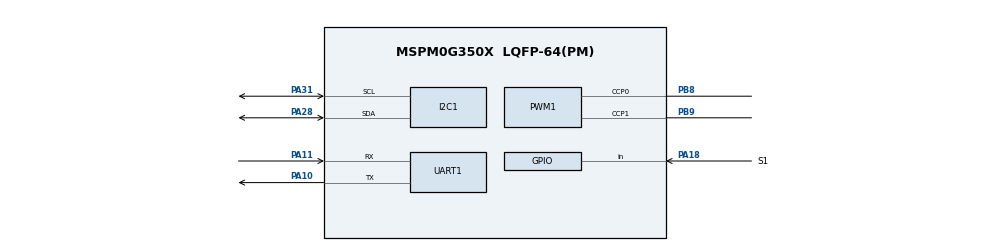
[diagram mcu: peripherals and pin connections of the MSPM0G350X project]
/**
 * @cliArgs --device "MSPM0G350X" --package "LQFP-64(PM)" --part "Default" --product "mspm0_sdk@2.01.00.03"
 * @versions {"tool":"1.20.0+3587"}
 */

/**
 * Import the modules used in this configuration.
 */
const GPIO   = scripting.addModule("/ti/driverlib/GPIO", {}, false);
const GPIO1  = GPIO.addInstance();
const GPIO2  = GPIO.addInstance();
const GPIO3  = GPIO.addInstance();
const GPIO4  = GPIO.addInstance();
const I2C    = scripting.addModule("/ti/driverlib/I2C", {}, false);
const I2C1   = I2C.addInstance();
const PWM    = scripting.addModule("/ti/driverlib/PWM", {}, false);
const PWM1   = PWM.addInstance();
const SYSCTL = scripting.addModule("/ti/driverlib/SYSCTL");
const TIMER  = scripting.addModule("/ti/driverlib/TIMER", {}, false);
const TIMER1 = TIMER.addInstance();
const UART   = scripting.addModule("/ti/driverlib/UART", {}, false);
const UART1  = UART.addInstance();
const UART2  = UART.addInstance();

/**
 * Write custom configuration values to the imported modules.
 */
const gate7  = system.clockTree["MFCLKGATE"];
gate7.enable = true;

GPIO1.$name                          = "GPIO_LEDS";
GPIO1.associatedPins.create(3);
GPIO1.associatedPins[0].$name        = "LED_1";
GPIO1.associatedPins[0].assignedPort = "PORTB";
GPIO1.associatedPins[0].assignedPin  = "22";
GPIO1.associatedPins[1].$name        = "LED_2";
GPIO1.associatedPins[1].assignedPort = "PORTB";
GPIO1.associatedPins[1].assignedPin  = "26";
GPIO1.associatedPins[2].$name        = "LED_3";
GPIO1.associatedPins[2].assignedPort = "PORTB";
GPIO1.associatedPins[2].assignedPin  = "27";

const Board = scripting.addModule("/ti/driverlib/Board", {}, false);

GPIO2.$name                              = "GPIO_KEYS";
GPIO2.associatedPins.create(2);
GPIO2.associatedPins[0].$name            = "S1";
GPIO2.associatedPins[0].direction        = "INPUT";
GPIO2.associatedPins[0].assignedPort     = "PORTA";
GPIO2.associatedPins[0].assignedPin      = "18";
GPIO2.associatedPins[0].internalResistor = "PULL_DOWN";
GPIO2.associatedPins[0].interruptEn      = true;
GPIO2.associatedPins[0].polarity         = "RISE_FALL";
GPIO2.associatedPins[0].pin.$assign      = "PA18";
GPIO2.associatedPins[1].$name            = "S2";
GPIO2.associatedPins[1].internalResistor = "PULL_UP";
GPIO2.associatedPins[1].assignedPort     = "PORTB";
GPIO2.associatedPins[1].assignedPin      = "21";
GPIO2.associatedPins[1].direction        = "INPUT";
GPIO2.associatedPins[1].interruptEn      = true;
GPIO2.associatedPins[1].polarity         = "RISE";

GPIO3.$name                          = "GPIO_Encoders";
GPIO3.associatedPins.create(4);
GPIO3.associatedPins[0].direction    = "INPUT";
GPIO3.associatedPins[0].assignedPort = "PORTB";
GPIO3.associatedPins[0].assignedPin  = "0";
GPIO3.associatedPins[0].interruptEn  = true;
GPIO3.associatedPins[0].polarity     = "RISE_FALL";
GPIO3.associatedPins[0].$name        = "M2_B0_TI1";
GPIO3.associatedPins[1].direction    = "INPUT";
GPIO3.associatedPins[1].assignedPort = "PORTB";
GPIO3.associatedPins[1].assignedPin  = "1";
GPIO3.associatedPins[1].polarity     = "RISE_FALL";
GPIO3.associatedPins[1].$name        = "M2_B1_TI2";
GPIO3.associatedPins[2].direction    = "INPUT";
GPIO3.associatedPins[2].polarity     = "RISE_FALL";
GPIO3.associatedPins[2].interruptEn  = true;
GPIO3.associatedPins[2].$name        = "M1_B3_TI1";
GPIO3.associatedPins[2].assignedPort = "PORTB";
GPIO3.associatedPins[2].assignedPin  = "3";
GPIO3.associatedPins[3].direction    = "INPUT";
GPIO3.associatedPins[3].interruptEn  = true;
GPIO3.associatedPins[3].polarity     = "RISE_FALL";
GPIO3.associatedPins[3].assignedPort = "PORTB";
GPIO3.associatedPins[3].assignedPin  = "2";
GPIO3.associatedPins[3].$name        = "M1_B2_TI2";

GPIO4.$name                          = "MPU6050";
GPIO4.associatedPins.create(2);
GPIO4.associatedPins[0].$name        = "MPU6050_SDA";
GPIO4.associatedPins[0].assignedPort = "PORTA";
GPIO4.associatedPins[0].assignedPin  = "8";
GPIO4.associatedPins[1].$name        = "MPU6050_SCL";
GPIO4.associatedPins[1].assignedPort = "PORTA";
GPIO4.associatedPins[1].assignedPin  = "9";

I2C1.$name                           = "I2C_0";
I2C1.basicControllerStandardBusSpeed = "Fast";
I2C1.basicEnableController           = true;
I2C1.peripheral.$assign              = "I2C0";
I2C1.peripheral.sdaPin.$assign       = "PA28";
I2C1.peripheral.sclPin.$assign       = "PA31";
I2C1.sdaPinConfig.$name              = "ti_driverlib_gpio_GPIOPinGeneric0";
I2C1.sclPinConfig.$name              = "ti_driverlib_gpio_GPIOPinGeneric1";

PWM1.$name                      = "PWM_0";
PWM1.clockPrescale              = 256;
PWM1.timerCount                 = 125;
PWM1.peripheral.$assign         = "TIMA0";
PWM1.peripheral.ccp0Pin.$assign = "PB8";
PWM1.peripheral.ccp1Pin.$assign = "PB9";
PWM1.PWM_CHANNEL_0.$name        = "ti_driverlib_pwm_PWMTimerCC0";
PWM1.PWM_CHANNEL_1.$name        = "ti_driverlib_pwm_PWMTimerCC1";
PWM1.ccp0PinConfig.$name        = "ti_driverlib_gpio_GPIOPinGeneric6";
PWM1.ccp1PinConfig.$name        = "ti_driverlib_gpio_GPIOPinGeneric7";

SYSCTL.forceDefaultClkConfig = true;
SYSCTL.clockTreeEn           = true;

TIMER1.$name              = "TIMER_0";
TIMER1.timerClkPrescale   = 256;
TIMER1.timerClkDiv        = 2;
TIMER1.timerPeriod        = "1s";
TIMER1.interrupts         = ["ZERO"];
TIMER1.timerMode          = "PERIODIC";
TIMER1.peripheral.$assign = "TIMA1";

UART1.$name                    = "UART_0";
UART1.targetBaudRate           = 115200;
UART1.uartClkSrc               = "MFCLK";
UART1.enabledInterrupts        = ["RX"];
UART1.peripheral.rxPin.$assign = "PA11";
UART1.peripheral.txPin.$assign = "PA10";
UART1.txPinConfig.$name        = "ti_driverlib_gpio_GPIOPinGeneric2";
UART1.rxPinConfig.$name        = "ti_driverlib_gpio_GPIOPinGeneric3";

UART2.$name              = "UART_1";
UART2.targetBaudRate     = 115200;
UART2.calculatedBaudRate = 1;
UART2.enabledInterrupts  = ["RX"];
UART2.txPinConfig.$name  = "ti_driverlib_gpio_GPIOPinGeneric4";
UART2.rxPinConfig.$name  = "ti_driverlib_gpio_GPIOPinGeneric5";

/**
 * Pinmux solution for unlocked pins/peripherals. This ensures that minor changes to the automatic solver in a future
 * version of the tool will not impact the pinmux you originally saw.  These lines can be completely deleted in order to
 * re-solve from scratch.
 */
GPIO1.associatedPins[0].pin.$suggestSolution = "PB22";
GPIO1.associatedPins[1].pin.$suggestSolution = "PB26";
GPIO1.associatedPins[2].pin.$suggestSolution = "PB27";
Board.peripheral.$suggestSolution            = "DEBUGSS";
Board.peripheral.swclkPin.$suggestSolution   = "PA20";
Board.peripheral.swdioPin.$suggestSolution   = "PA19";
GPIO2.associatedPins[1].pin.$suggestSolution = "PB21";
GPIO3.associatedPins[0].pin.$suggestSolution = "PB0";
GPIO3.associatedPins[1].pin.$suggestSolution = "PB1";
GPIO3.associatedPins[2].pin.$suggestSolution = "PB3";
GPIO3.associatedPins[3].pin.$suggestSolution = "PB2";
GPIO4.associatedPins[0].pin.$suggestSolution = "PA8";
GPIO4.associatedPins[1].pin.$suggestSolution = "PA9";
UART1.peripheral.$suggestSolution            = "UART0";
UART2.peripheral.$suggestSolution            = "UART1";
UART2.peripheral.rxPin.$suggestSolution      = "PB5";
UART2.peripheral.txPin.$suggestSolution      = "PA17";
